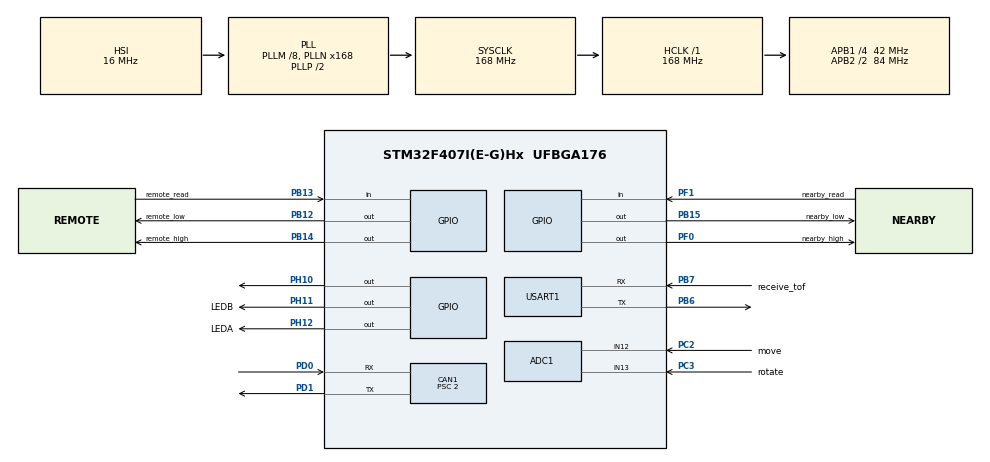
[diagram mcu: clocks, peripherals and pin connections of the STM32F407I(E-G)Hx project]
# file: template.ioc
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ADC1.Channel-0\#ChannelRegularConversion=ADC_CHANNEL_12
ADC1.Channel-1\#ChannelRegularConversion=ADC_CHANNEL_13
ADC1.ContinuousConvMode=ENABLE
ADC1.NbrOfConversion=2
ADC1.NbrOfConversionFlag=1
ADC1.Rank-0\#ChannelRegularConversion=1
ADC1.Rank-1\#ChannelRegularConversion=2
ADC1.SamplingTime-0\#ChannelRegularConversion=ADC_SAMPLETIME_3CYCLES
ADC1.SamplingTime-1\#ChannelRegularConversion=ADC_SAMPLETIME_3CYCLES
ADC1.ScanConvMode=ENABLE
ADC1.master=1
CAN1.BS1=CAN_BS1_16TQ
CAN1.BS2=CAN_BS2_4TQ
CAN1.CalculateBaudRate=1000000
CAN1.CalculateTimeBit=1000
CAN1.CalculateTimeQuantum=47.61904761904762
CAN1.Mode=CAN_MODE_NORMAL
CAN1.NART=ENABLE
CAN1.Prescaler=2
CAN1.TXFP=DISABLE
Dma.ADC1.0.Direction=DMA_PERIPH_TO_MEMORY
Dma.ADC1.0.FIFOMode=DMA_FIFOMODE_DISABLE
Dma.ADC1.0.Instance=DMA2_Stream0
Dma.ADC1.0.MemDataAlignment=DMA_MDATAALIGN_WORD
Dma.ADC1.0.MemInc=DMA_MINC_ENABLE
Dma.ADC1.0.Mode=DMA_CIRCULAR
Dma.ADC1.0.PeriphDataAlignment=DMA_PDATAALIGN_WORD
Dma.ADC1.0.PeriphInc=DMA_PINC_DISABLE
Dma.ADC1.0.Priority=DMA_PRIORITY_LOW
Dma.Request0=ADC1
Mcu.Family=STM32F4
Mcu.Name=STM32F407I(E-G)Hx
Mcu.Package=UFBGA176
NVIC.CAN1_RX0_IRQn=true\:0\:0\:true\:false\:true\:true\:true\:true
NVIC.DMA2_Stream0_IRQn=true\:0\:0\:false\:false\:true\:false\:true\:true
NVIC.PriorityGroup=NVIC_PRIORITYGROUP_4
NVIC.TIM8_TRG_COM_TIM14_IRQn=true\:2\:0\:true\:false\:true\:true\:true\:true
NVIC.USART1_IRQn=true\:0\:0\:false\:false\:true\:true\:true\:true
PA13.Mode=Serial_Wire
PA13.Signal=SYS_JTMS-SWDIO
PA14.Mode=Serial_Wire
PA14.Signal=SYS_JTCK-SWCLK
PB12.GPIO_Label=remote_low
PB12.GPIO_PuPd=GPIO_PULLUP
PB12.Signal=GPIO_Output
PB13.GPIO_Label=remote_read
PB13.GPIO_PuPd=GPIO_PULLUP
PB13.Signal=GPIO_Input
PB14.GPIO_Label=remote_high
PB14.GPIO_PuPd=GPIO_PULLUP
PB14.PinState=GPIO_PIN_SET
PB14.Signal=GPIO_Output
PB15.GPIO_Label=nearby_low
PB15.Signal=GPIO_Output
PB6.Mode=Asynchronous
PB6.Signal=USART1_TX
PB7.GPIO_Label=receive_tof
PB7.Mode=Asynchronous
PB7.Signal=USART1_RX
PC14-OSC32_IN.Mode=LSE-External-Oscillator
PC14-OSC32_IN.Signal=RCC_OSC32_IN
PC15-OSC32_OUT.Mode=LSE-External-Oscillator
PC15-OSC32_OUT.Signal=RCC_OSC32_OUT
PC2.GPIO_Label=move
PC2.Signal=ADCx_IN12
PC3.GPIO_Label=rotate
PC3.Signal=ADCx_IN13
PD0.Mode=CAN_Activate
PD0.Signal=CAN1_RX
PD1.Mode=CAN_Activate
PD1.Signal=CAN1_TX
PF0.GPIO_Label=nearby_high
PF0.GPIO_PuPd=GPIO_PULLUP
PF0.PinState=GPIO_PIN_SET
PF0.Signal=GPIO_Output
PF1.GPIO_Label=nearby_read
PF1.GPIO_PuPd=GPIO_PULLUP
PF1.Signal=GPIO_Input
PH0-OSC_IN.Mode=HSE-External-Oscillator
PH0-OSC_IN.Signal=RCC_OSC_IN
PH1-OSC_OUT.Mode=HSE-External-Oscillator
PH1-OSC_OUT.Signal=RCC_OSC_OUT
PH10.Signal=GPIO_Output
PH11.GPIO_Label=LEDB
PH11.Signal=GPIO_Output
PH12.GPIO_Label=LEDA
PH12.Signal=GPIO_Output
ProjectManager.HeapSize=0x200
ProjectManager.StackSize=0x400
ProjectManager.TargetToolchain=CMake
RCC.48MHZClocksFreq_Value=84000000
RCC.AHBFreq_Value=168000000
RCC.APB1CLKDivider=RCC_HCLK_DIV4
RCC.APB1Freq_Value=42000000
RCC.APB1TimFreq_Value=84000000
RCC.APB2CLKDivider=RCC_HCLK_DIV2
RCC.APB2Freq_Value=84000000
RCC.APB2TimFreq_Value=168000000
RCC.CortexFreq_Value=168000000
RCC.HCLKFreq_Value=168000000
RCC.HSE_VALUE=12000000
RCC.HSI_VALUE=16000000
RCC.PLLM=8
RCC.PLLN=168
RCC.SYSCLKFreq_VALUE=168000000
RCC.SYSCLKSource=RCC_SYSCLKSOURCE_PLLCLK
RCC.VCOOutputFreq_Value=336000000
SH.ADCx_IN12.0=ADC1_IN12,IN12
SH.ADCx_IN13.0=ADC1_IN13,IN13
TIM14.Period=1000-1
TIM14.Prescaler=8400-1
USART1.VirtualMode=VM_ASYNC
VP_TIM14_VS_ClockSourceINT.Mode=Enable_Timer
board=custom

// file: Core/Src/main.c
/* USER CODE BEGIN Header */
/**
 ******************************************************************************
 * @file           : main.c
 * @brief          : Main program body
 ******************************************************************************
 * @attention
 *
 * Copyright (c) 2024 STMicroelectronics.
 * All rights reserved.
 *
 * This software is licensed under terms that can be found in the LICENSE file
 * in the root directory of this software component.
 * If no LICENSE file comes with this software, it is provided AS-IS.
 *
 ******************************************************************************
 */
/* USER CODE END Header */
#include "main.h"
#include "adc.h"
#include "can.h"
#include "dma.h"
#include "tim.h"
#include "usart.h"
#include "gpio.h"

/* USER CODE BEGIN Includes */
#include "entrypoint.hh"
/* USER CODE END Includes */

void SystemClock_Config(void);
/* USER CODE BEGIN PFP */
extern void entrypoint();
/* USER CODE END PFP */

int main(void)
{

  /* MCU Configuration--------------------------------------------------------*/

  /* Reset of all peripherals, Initializes the Flash interface and the Systick. */
  HAL_Init();

  /* Configure the system clock */
  SystemClock_Config();

  /* Initialize all configured peripherals */
  MX_GPIO_Init();
  MX_DMA_Init();
  MX_CAN1_Init();
  MX_TIM14_Init();
  MX_USART1_UART_Init();
  MX_ADC1_Init();
  /* USER CODE BEGIN 2 */
    entrypoint();
  /* USER CODE END 2 */

  /* Infinite loop */
    while (1) {
    }

}

void SystemClock_Config(void)
{
  RCC_OscInitTypeDef RCC_OscInitStruct = {0};
  RCC_ClkInitTypeDef RCC_ClkInitStruct = {0};

  /** Configure the main internal regulator output voltage
  */
  __HAL_RCC_PWR_CLK_ENABLE();
  __HAL_PWR_VOLTAGESCALING_CONFIG(PWR_REGULATOR_VOLTAGE_SCALE1);

  /** Initializes the RCC Oscillators according to the specified parameters
  * in the RCC_OscInitTypeDef structure.
  */
  RCC_OscInitStruct.OscillatorType = RCC_OSCILLATORTYPE_HSI;
  RCC_OscInitStruct.HSIState = RCC_HSI_ON;
  RCC_OscInitStruct.HSICalibrationValue = RCC_HSICALIBRATION_DEFAULT;
  RCC_OscInitStruct.PLL.PLLState = RCC_PLL_ON;
  RCC_OscInitStruct.PLL.PLLSource = RCC_PLLSOURCE_HSI;
  RCC_OscInitStruct.PLL.PLLM = 8;
  RCC_OscInitStruct.PLL.PLLN = 168;
  RCC_OscInitStruct.PLL.PLLP = RCC_PLLP_DIV2;
  RCC_OscInitStruct.PLL.PLLQ = 4;
  if (HAL_RCC_OscConfig(&RCC_OscInitStruct) != HAL_OK)
  {
    Error_Handler();
  }

  /** Initializes the CPU, AHB and APB buses clocks
  */
  RCC_ClkInitStruct.ClockType = RCC_CLOCKTYPE_HCLK|RCC_CLOCKTYPE_SYSCLK
                              |RCC_CLOCKTYPE_PCLK1|RCC_CLOCKTYPE_PCLK2;
  RCC_ClkInitStruct.SYSCLKSource = RCC_SYSCLKSOURCE_PLLCLK;
  RCC_ClkInitStruct.AHBCLKDivider = RCC_SYSCLK_DIV1;
  RCC_ClkInitStruct.APB1CLKDivider = RCC_HCLK_DIV4;
  RCC_ClkInitStruct.APB2CLKDivider = RCC_HCLK_DIV2;

  if (HAL_RCC_ClockConfig(&RCC_ClkInitStruct, FLASH_LATENCY_5) != HAL_OK)
  {
    Error_Handler();
  }
}

void Error_Handler(void)
{
    __disable_irq();
    while (1) {
    }
}
